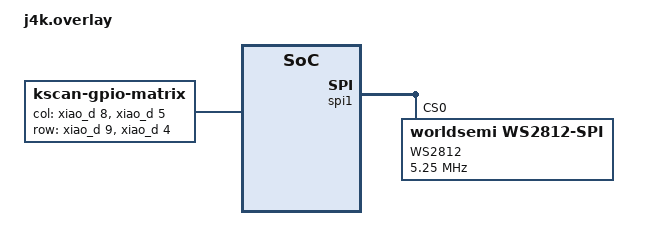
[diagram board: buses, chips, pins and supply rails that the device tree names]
/*
 * Copyright (c) 2021 The ZMK Contributors
 *
 * SPDX-License-Identifier: MIT
 */


&xiao_spi { status = "enabled"; };
&xiao_i2c { status = "enabled"; };
&xiao_serial { status = "enabled"; };


#include <dt-bindings/zmk/matrix_transform.h>

/ {
	chosen {
		zmk,kscan = &kscan0;
		zmk,underglow = &led_strip;
	};

	kscan0: kscan {
		compatible = "zmk,kscan-gpio-matrix";
		label = "KSCAN";

		diode-direction = "col2row";
			col-gpios
					= <&xiao_d 8 (GPIO_ACTIVE_HIGH)>
					, <&xiao_d 5 (GPIO_ACTIVE_HIGH)>
					;
			row-gpios
					= <&xiao_d 9 (GPIO_ACTIVE_HIGH | GPIO_PULL_DOWN)>
					, <&xiao_d 4 (GPIO_ACTIVE_HIGH | GPIO_PULL_DOWN)>
					;
	};
};

#include <dt-bindings/led/led.h>

&spi1 {

  led_strip: ws2812@0 {
    compatible = "worldsemi,ws2812-spi";
    label = "WS2812";

    /* SPI */
    reg = <0>;
    spi-max-frequency = <5250000>;

    /* WS2812 */
    chain-length = <4>; /* number of LEDs */
    spi-one-frame = <0x70>; /* make sure to configure this properly for your SOC */
    spi-zero-frame = <0x40>; /* make sure to configure this properly for your SOC */
    color-mapping = <LED_COLOR_ID_GREEN
                          LED_COLOR_ID_RED
                          LED_COLOR_ID_BLUE>;
  };
};
